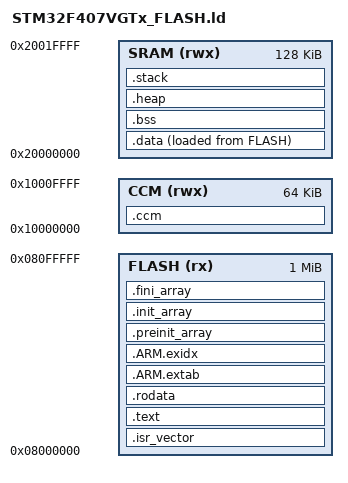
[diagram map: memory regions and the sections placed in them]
/* Ducktop2 EC - STM32F407VGT6 Linker Script */

MEMORY
{
    FLASH  (rx)  : ORIGIN = 0x08000000, LENGTH = 1024K
    SRAM   (rwx) : ORIGIN = 0x20000000, LENGTH = 128K
    CCM    (rwx) : ORIGIN = 0x10000000, LENGTH = 64K
}

_estack = ORIGIN(SRAM) + LENGTH(SRAM);

SECTIONS
{
    .isr_vector :
    {
        . = ALIGN(4);
        KEEP(*(.isr_vector))
        . = ALIGN(4);
    } > FLASH

    .text :
    {
        . = ALIGN(4);
        *(.text)
        *(.text*)
        *(.glue_7)
        *(.glue_7t)
        *(.gnu.linkonce.t*)
        . = ALIGN(4);
    } > FLASH

    .rodata :
    {
        . = ALIGN(4);
        *(.rodata)
        *(.rodata*)
        *(.gnu.linkonce.r*)
        . = ALIGN(4);
    } > FLASH

    .ARM.extab :
    {
        . = ALIGN(4);
        *(.ARM.extab*)
        *(.gnu.linkonce.armextab.*)
        . = ALIGN(4);
    } > FLASH

    .ARM.exidx :
    {
        . = ALIGN(4);
        __exidx_start = .;
        *(.ARM.exidx*)
        *(.gnu.linkonce.armexidx.*)
        __exidx_end = .;
        . = ALIGN(4);
    } > FLASH

    .preinit_array :
    {
        . = ALIGN(4);
        PROVIDE_HIDDEN(__preinit_array_start = .);
        KEEP(*(.preinit_array*))
        PROVIDE_HIDDEN(__preinit_array_end = .);
        . = ALIGN(4);
    } > FLASH

    .init_array :
    {
        . = ALIGN(4);
        PROVIDE_HIDDEN(__init_array_start = .);
        KEEP(*(SORT(.init_array.*)))
        KEEP(*(.init_array*))
        PROVIDE_HIDDEN(__init_array_end = .);
        . = ALIGN(4);
    } > FLASH

    .fini_array :
    {
        . = ALIGN(4);
        PROVIDE_HIDDEN(__fini_array_start = .);
        KEEP(*(SORT(.fini_array.*)))
        KEEP(*(.fini_array*))
        PROVIDE_HIDDEN(__fini_array_end = .);
        . = ALIGN(4);
    } > FLASH

    _sidata = LOADADDR(.data);

    .data :
    {
        . = ALIGN(4);
        _sdata = .;
        *(.data)
        *(.data*)
        . = ALIGN(4);
        _edata = .;
    } > SRAM AT > FLASH

    .bss :
    {
        . = ALIGN(4);
        _sbss = .;
        __bss_start__ = .;
        *(.bss)
        *(.bss*)
        *(COMMON)
        . = ALIGN(4);
        _ebss = .;
        __bss_end__ = .;
    } > SRAM

    .ccm (NOLOAD) :
    {
        . = ALIGN(4);
        _sccm = .;
        *(.ccm)
        *(.ccm*)
        . = ALIGN(4);
        _eccm = .;
    } > CCM

    .heap (COPY) :
    {
        . = ALIGN(8);
        _sheap = .;
        . = . + 0x400;
        . = ALIGN(8);
        _eheap = .;
    } > SRAM

    .stack (COPY) :
    {
        . = ALIGN(8);
        _sstack = .;
        . = . + 0x800;
        . = ALIGN(8);
        _estack = .;
    } > SRAM

    /DISCARD/ :
    {
    }
}
